# VREF_1.0 register map
Vendor: Texas Instruments
Peripheral module from a debugger description file (folder mspm0l11xx_l13xx).
Registers are 32-bit, read-write, no defined reset value unless marked. A register's access mark holds for its fields unless they carry their own. Offsets are as the file gives them; lines under a group give offsets from that group; [hi:lo] are bit positions; {n}, {i} and the like mark numbered series; 'fields as' and 'values as' point back to an identical list; <NAME> marks a mode.

## VREF
0x800 VREF_GPRCM group
  0x00 VREF_PWREN — Power enable
    [0] ENABLE — Enable the power
      0=DISABLE (Disable Power); 1=ENABLE (Enable Power)
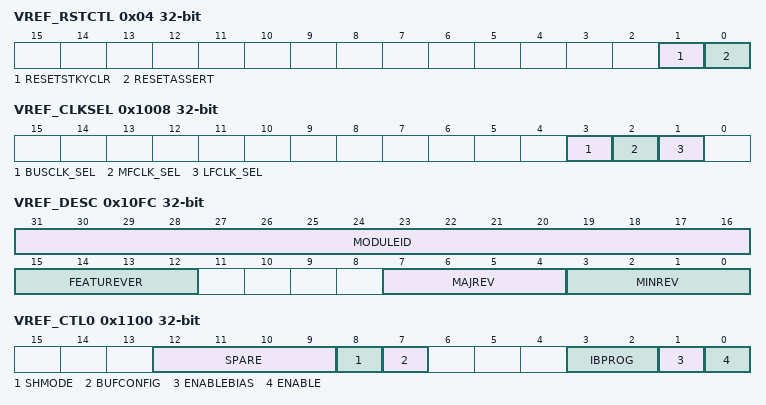
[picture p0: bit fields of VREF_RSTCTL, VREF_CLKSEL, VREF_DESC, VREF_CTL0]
  0x04 VREF_RSTCTL — Reset Control
    [1] RESETSTKYCLR — Clear the RESETSTKY bit in the STAT register
      0=NOP (Writing 0 has no effect); 1=CLR (Clear reset sticky bit)
    [0] RESETASSERT — Assert reset to the peripheral
      0=NOP (Writing 0 has no effect); 1=ASSERT (Assert reset)
  0x14 VREF_STAT ro — Status Register
    [16] RESETSTKY — This bit indicates, if the peripheral was reset, since this bit was cleared by RESETSTKYCLR in the RSTCTL register
      0=NORES (The peripheral has not been reset since this bit was last cleared by RESETSTKYCLR in the RSTCTL register); 1=RESET (The peripheral was reset since the last bit clear)
0x1000 VREF_CLKDIV — Clock Divider
  [2:0] RATIO — Selects divide ratio of module clock
0x1008 VREF_CLKSEL — Clock Selection
  [3] BUSCLK_SEL — Selects BUSCLK as clock source if enabled
  [2] MFCLK_SEL — Selects MFCLK as clock source if enabled
  [1] LFCLK_SEL — Selects LFCLK as clock source if enabled
0x10FC VREF_DESC ro — Module Description
  [31:16] MODULEID — Module identification contains a unique peripheral identification number. The assignments are maintained in a central database for all of the platform modules to ensure uniqueness.
  [15:12] FEATUREVER — Feature Set for the module *instance*
  [7:4] MAJREV — Major rev of the IP
  [3:0] MINREV — Minor rev of the IP
0x1100 VREF_CTL0 — Control 0
  [12:9] SPARE — These bits are reserved
  [8] SHMODE — This bit enable sample and hold mode
    0=DISABLE (Sample and hold mode is disable); 1=Enable (Sample and hold mode is enable)
  [7] BUFCONFIG — These bits configure output buffer.
    0=OUTPUT2P5V (Configure Output Buffer to 2.5v); 1=OUTPUT1P4V (Configure Output Buffer to 1.4v)
  [3:2] IBPROG — There bits configure current bias.
    0=NOMIBIAS (Nominal Ibias setting.); 1=Ibias Program Option b01: TheFlash: Increase Ibias by 30% LordBusiness: Reduce Ibias by 50%; 2=Ibias Program Option b10: TheFlash: Reduce Ibias by 35% LordBusiness: Increase Ibias by 50%; 3=Ibias Program Option b11: TheFlash: Nominal Ibias LordBusiness: Reduce Ibias by 33%
  [1] ENABLEBIAS — This bit enables the VREF Bias.
    0=DISABLE (IBIAS is disable); 1=ENABLE (IBIAS is enable)
  [0] ENABLE — This bit enables the VREF module.
    0=DISABLE (VREF is disabled); 1=ENABLE (VREF is enabled)
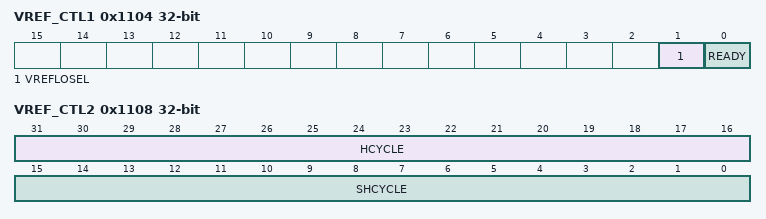
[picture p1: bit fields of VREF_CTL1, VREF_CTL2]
0x1104 VREF_CTL1 access per field — Control 1
  [1] VREFLOSEL rw — This bit select VREFLO pin
  [0] READY ro — These bits defines status of VREF
    0=NOTRDY (VREF output is not ready); 1=RDY (VREF output is ready)
0x1108 VREF_CTL2 — Control 2
  [31:16] HCYCLE — Hold cycle count
    0=MINIMUM (smallest hold cycle); 0xFFFF=MAXIMUM (largest hold cycle)
  [15:0] SHCYCLE — Sample and hold cycle count
    0=MINIMUM (smallest sample and hold cycle count); 0xFFFF=MAXIMUM (largest sample and hold cycle)
